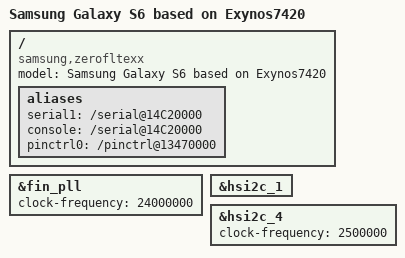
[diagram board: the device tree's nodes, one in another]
// SPDX-License-Identifier: GPL-2.0+

#include "exynos7420.dtsi"
/ {
	model = "Samsung Galaxy S6 based on Exynos7420";
	compatible = "samsung,zerofltexx", "samsung,exynos7420";

	aliases {
		serial1 = "/serial@14C20000";
		console = "/serial@14C20000";
		pinctrl0 = "/pinctrl@13470000";
	};
};

&fin_pll {
	clock-frequency = <24000000>;
};

&hsi2c_1 {
	status = "okay";
};

&hsi2c_4 {
	status = "okay";
	clock-frequency = <2500000>;
};
